AUTOSAR XML (schema 4-2-2)
package /STELLANTIS/EPT/ASWCs
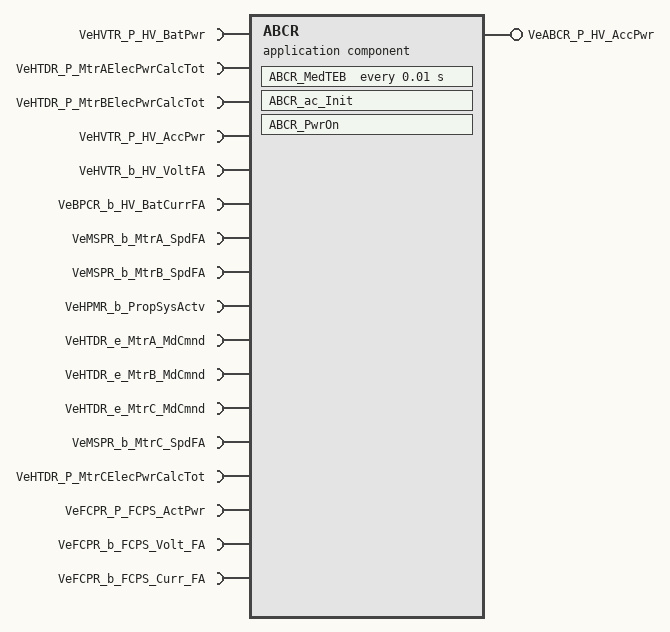
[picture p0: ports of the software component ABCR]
  application sw component type ABCR
    17 x require port:
      VeHVTR_P_HV_BatPwr: nonqueued-receiver-com-spec{data-element=Value, init-value=0}, required-interface=VeHVTR_P_HV_BatPwr
      VeHTDR_P_MtrAElecPwrCalcTot: nonqueued-receiver-com-spec{data-element=Value, init-value=0}, required-interface=VeHTDR_P_MtrAElecPwrCalcTot
      VeHTDR_P_MtrBElecPwrCalcTot: nonqueued-receiver-com-spec{data-element=Value, init-value=0}, required-interface=VeHTDR_P_MtrBElecPwrCalcTot
      VeHVTR_P_HV_AccPwr: nonqueued-receiver-com-spec{data-element=Value, init-value=0}, required-interface=VeHVTR_P_HV_AccPwr
      VeHVTR_b_HV_VoltFA: nonqueued-receiver-com-spec{data-element=Value, init-value=0}, required-interface=VeHVTR_b_HV_VoltFA
      VeBPCR_b_HV_BatCurrFA: nonqueued-receiver-com-spec{data-element=Value, init-value=0}, required-interface=VeBPCR_b_HV_BatCurrFA
      VeMSPR_b_MtrA_SpdFA: nonqueued-receiver-com-spec{data-element=Value, init-value=0}, required-interface=VeMSPR_b_MtrA_SpdFA
      VeMSPR_b_MtrB_SpdFA: nonqueued-receiver-com-spec{data-element=Value, init-value=0}, required-interface=VeMSPR_b_MtrB_SpdFA
      VeHPMR_b_PropSysActv: nonqueued-receiver-com-spec{data-element=Value, init-value=0}, required-interface=VeHPMR_b_PropSysActv
      VeHTDR_e_MtrA_MdCmnd: nonqueued-receiver-com-spec{data-element=Value, init-value=CeHTDR_e_DsblNoSwitch}, required-interface=VeHTDR_e_MtrA_MdCmnd
      VeHTDR_e_MtrB_MdCmnd: nonqueued-receiver-com-spec{data-element=Value, init-value=CeHTDR_e_DsblNoSwitch}, required-interface=VeHTDR_e_MtrB_MdCmnd
      VeHTDR_e_MtrC_MdCmnd: nonqueued-receiver-com-spec{data-element=Value, init-value=CeHTDR_e_DsblNoSwitch}, required-interface=VeHTDR_e_MtrC_MdCmnd
      VeMSPR_b_MtrC_SpdFA: nonqueued-receiver-com-spec{data-element=Value, init-value=0}, required-interface=VeMSPR_b_MtrC_SpdFA
      VeHTDR_P_MtrCElecPwrCalcTot: nonqueued-receiver-com-spec{data-element=Value, init-value=0}, required-interface=VeHTDR_P_MtrCElecPwrCalcTot
      VeFCPR_P_FCPS_ActPwr: nonqueued-receiver-com-spec{data-element=Value, init-value=0}, required-interface=VeFCPR_P_FCPS_ActPwr
      VeFCPR_b_FCPS_Volt_FA: nonqueued-receiver-com-spec{data-element=Value, init-value=0}, required-interface=VeFCPR_b_FCPS_Volt_FA
      VeFCPR_b_FCPS_Curr_FA: nonqueued-receiver-com-spec{data-element=Value, init-value=0}, required-interface=VeFCPR_b_FCPS_Curr_FA
    provide port VeABCR_P_HV_AccPwr: nonqueued-sender-com-spec{data-element=Value, init-value=0}, provided-interface=VeABCR_P_HV_AccPwr
    behavior IB_ABCR: data-type-mapping=msADTtoIDTMapping, handle-termination-and-restart=NO-SUPPORT
      timing event Event_MedTEB: start-on-event=ABCR_MedTEB, period=0.01
      init event Event_ABCR_ac_Init: start-on-event=ABCR_ac_Init
      init event Event_PwrOn: start-on-event=ABCR_PwrOn
      runnable ABCR_ac_Init
        data-send-points:
          access OUT_VeABCR_P_HV_AccPwr_Value: accessed-variable=VeABCR_P_HV_AccPwr.Value
      runnable ABCR_PwrOn
        data-send-points:
          access OUT_VeABCR_P_HV_AccPwr_Value: accessed-variable=VeABCR_P_HV_AccPwr.Value
      runnable ABCR_MedTEB
        data-receive-point-by-arguments:
          17 x access:
            IN_VeBPCR_b_HV_BatCurrFA_Value: accessed-variable=VeBPCR_b_HV_BatCurrFA.Value
            IN_VeFCPR_P_FCPS_ActPwr_Value: accessed-variable=VeFCPR_P_FCPS_ActPwr.Value
            IN_VeFCPR_b_FCPS_Curr_FA_Value: accessed-variable=VeFCPR_b_FCPS_Curr_FA.Value
            IN_VeFCPR_b_FCPS_Volt_FA_Value: accessed-variable=VeFCPR_b_FCPS_Volt_FA.Value
            IN_VeHPMR_b_PropSysActv_Value: accessed-variable=VeHPMR_b_PropSysActv.Value
            IN_VeHTDR_P_MtrAElecPwrCalcTot_Value: accessed-variable=VeHTDR_P_MtrAElecPwrCalcTot.Value
            IN_VeHTDR_P_MtrBElecPwrCalcTot_Value: accessed-variable=VeHTDR_P_MtrBElecPwrCalcTot.Value
            IN_VeHTDR_P_MtrCElecPwrCalcTot_Value: accessed-variable=VeHTDR_P_MtrCElecPwrCalcTot.Value
            IN_VeHTDR_e_MtrA_MdCmnd_Value: accessed-variable=VeHTDR_e_MtrA_MdCmnd.Value
            IN_VeHTDR_e_MtrB_MdCmnd_Value: accessed-variable=VeHTDR_e_MtrB_MdCmnd.Value
            IN_VeHTDR_e_MtrC_MdCmnd_Value: accessed-variable=VeHTDR_e_MtrC_MdCmnd.Value
            IN_VeHVTR_P_HV_AccPwr_Value: accessed-variable=VeHVTR_P_HV_AccPwr.Value
            IN_VeHVTR_P_HV_BatPwr_Value: accessed-variable=VeHVTR_P_HV_BatPwr.Value
            IN_VeHVTR_b_HV_VoltFA_Value: accessed-variable=VeHVTR_b_HV_VoltFA.Value
            IN_VeMSPR_b_MtrA_SpdFA_Value: accessed-variable=VeMSPR_b_MtrA_SpdFA.Value
            IN_VeMSPR_b_MtrB_SpdFA_Value: accessed-variable=VeMSPR_b_MtrB_SpdFA.Value
            IN_VeMSPR_b_MtrC_SpdFA_Value: accessed-variable=VeMSPR_b_MtrC_SpdFA.Value
        data-send-points:
          access OUT_VeABCR_P_HV_AccPwr_Value: accessed-variable=VeABCR_P_HV_AccPwr.Value
